# a31g22x register map
Vendor: ABOV Semiconductor Co., Ltd.; Series: a31g22x; File version: 0.2
CPU: CM0PLUS r0p1, little endian, no MPU, no FPU, VTOR, 2 interrupt priority bits
Registers are 32-bit, read-write, reset 0x0 unless marked. A register's access mark holds for its fields unless they carry their own. Offsets are from the block's base; [hi:lo] are bit positions.

## UART0 — UNIVERSAL ASYNCHRONOUS RECEIVER/TRANSMITTER
Base 0x40004000
Same registers: UART1 0x40004100
0x00 RBR ro — UARTn Receive Buffer Register
  [7:0] RBR — recevied/transmit data
0x00 THR wo — UARTn Transmit Data Hold Register
  [7:0] THR — recevied/transmit data
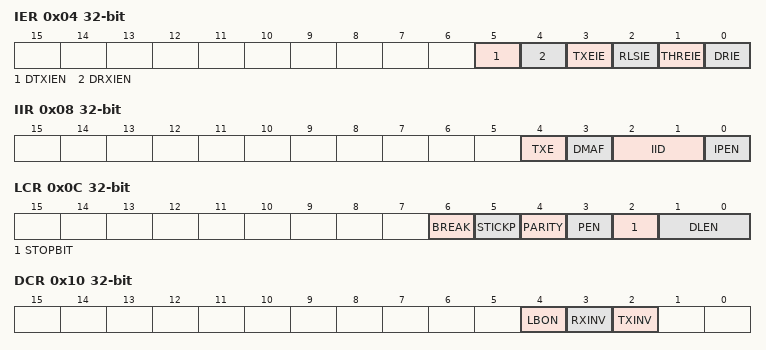
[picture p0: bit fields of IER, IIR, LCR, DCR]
0x04 IER — UARTn Interrupt Enable Register
  [5] DTXIEN — DMA Transmit done Interrupt Enable
  [4] DRXIEN — DMA Receiver done Interrupt Enable
  [3] TXEIE — Transmit Register Empty Interrupt Enable
  [2] RLSIE — Receiver Line Status Interrupt Enable
  [1] THREIE — Transmit Holding Register Empty Interrupt Enable
  [0] DRIE — Data Receive Interrupt Enable
0x08 IIR — UARTn Interrupt ID Register
  [4] TXE — Transmit Complete Interrupt Source ID bit
  [3] DMAF — UARTn DMA Flag bits
    0=DMA_PEND (During DMA operation or No DMA); 1=DMA_DONE (Done DMA operation)
  [2:1] IID — UARTn Interrupt ID bits
  [0] IPEN — Interrupt Pending bit
0x0C LCR — UARTn Line Control Register
  [6] BREAK — Transfer Break Control The TXDn pin will be driven at low state in order to notice the alert to the receiver
  [5] STICKP — Force Parity bit. This bit is effective when the PEN bit is set to 1b
  [4] PARITY — Parity Mode and Parity Stuck Selection
  [3] PEN — parity bit transfer enable
  [2] STOPBIT — Stop Bit Length Selection
  [1:0] DLEN — Data Length Selection
0x10 DCR — UARTn Data Control Register
  [4] LBON — Local loopback test mode enable
  [3] RXINV — Rx Data Inversion selection
  [2] TXINV — TX Data Inversion selection
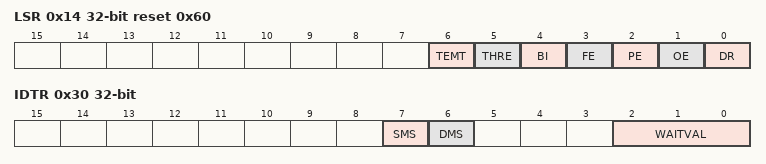
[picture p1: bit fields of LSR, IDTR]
0x14 LSR reset 0x60 — UARTn Line Status Register
  [6] TEMT — Transmit Empty
  [5] THRE — Transmit Holding Register Empty
  [4] BI — Break condition Indication
  [3] FE — Frame Error indicator
  [2] PE — Parity Error indicator
  [1] OE — Overrun Error indicator
  [0] DR — Data Recevie indicator
0x20 BDR — UARTn Baud rate Divisor Latch Register
  [15:0] BDR — Baud rate Divider latch value
0x24 BFR — UARTn Baud rate Fraction Counter Register
  [7:0] BFR — Baud rate Fraction counter value
0x30 IDTR — UARTn Inter-frame Delay Time Register
  [7] SMS — Start Bit Multi Sampling Enable
  [6] DMS — Data bit Multi Sampling enable
  [2:0] WAITVAL — wait time is decied by this value

## SPI20 — SERIAL PERIPHERAL INTERFACE
Base 0x40004C00
Same registers: SPI21 0x40004D00
0x00 TDR wo — SPI n Transmit Data Register
  [16:0] TDR — Transmit Data Bit
0x00 RDR ro — SPI n Received Data Register
  [16:0] RDR — Received Data Bit
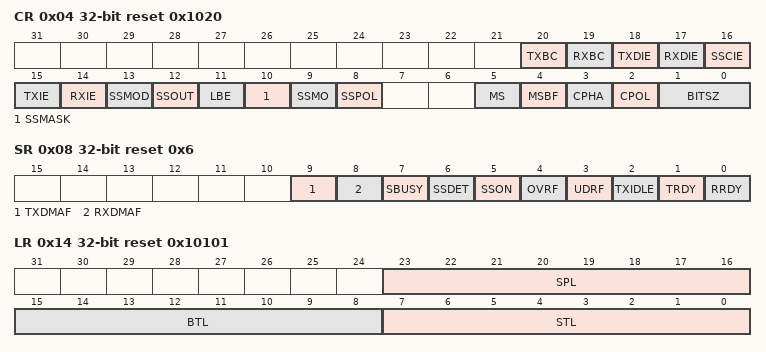
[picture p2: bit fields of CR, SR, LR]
0x04 CR reset 0x1020 — SPI n Control Register
  [20] TXBC — Tx Buffer Clear Bit
  [19] RXBC — Rx Buffer Clear Bit
  [18] TXDIE — DMA Tx Complete Interrupt Enable Bit
  [17] RXDIE — DMA Rx Complete Interrupt Enable Bit
  [16] SSCIE — SS Edge Changed Interrupt Enable Bit
  [15] TXIE — Transmit Interrupt Enable Bit
  [14] RXIE — Received Interrupt Enable Bit
  [13] SSMOD — SS Auto/Manual Output Selection Bit in Master Mode
  [12] SSOUT — SS Output Signal Control Bit
  [11] LBE — Loop-back Mode Selection Bit in Master Mode
  [10] SSMASK — SS Signal Masking in Slave Mode
  [9] SSMO — SS Output Signal Selection Bit
  [8] SSPOL — SS Signal Polarity Selection Bit
  [5] MS — Master/Slave Selection Bit
  [4] MSBF — MSB/LSB Transmit Advance Selection Bit
  [3] CPHA — SPI Clock Phase Bit
  [2] CPOL — SPI Clock Polarity Bit
  [1:0] BITSZ — Transmit/Receive Bit Size Selection Bit
    0=8_BIT (Size is 8 bit); 1=9_BIT (Size is 9 bit); 2=16_BIT (Size is 16 bit); 3=17_BIT (Size is 17 bit)
0x08 SR reset 0x6 — SPI n Status Register
  [9] TXDMAF — DMA Transmit Operation Complete Flag
  [8] RXDMAF — DMA Received Operation Complete Flag
  [7] SBUSY ro — Transmit/Received Operating Flag
  [6] SSDET — SS Signal Rising or Falling Edge Detected Flag
  [5] SSON — SS Signal Status Flag
  [4] OVRF — Received Overrun Error Flag
  [3] UDRF — Transmit Underrun Error Flag
  [2] TXIDLE ro — Transmit Operating Flag
  [1] TRDY ro — Transmit Buffer Empty Flag
  [0] RRDY ro — Received Buffer Empty Flag
0x0C BR reset 0xFFFF — SPI n Baud Rate Register
  [15:0] BR — Baud Rate Setting Bit
0x10 EN — SPI n Enable Register
  [0] ENABLE — SPI Enable Bit
0x14 LR reset 0x10101 — SPI n Delay Length Register
  [23:16] SPL — STOP Length Value Bit
  [15:8] BTL — Burst Length Value Bit
  [7:0] STL — Start Length Value Bit
